# ATmega6490P device description
Architecture: AVR8; Family: megaAVR
Registers are 8-bit, access not given, no defined reset value unless marked. A register's access mark holds for its fields unless they carry their own. Offsets are from the block's base; [hi:lo] are bit positions; {n}, {i} and the like mark numbered series.

## TC0 (TC8 module) — Timer/Counter, 8-bit
Instances: TC0 0x00
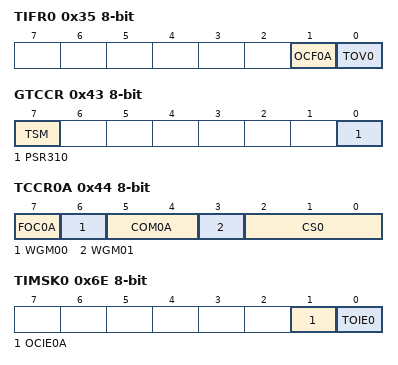
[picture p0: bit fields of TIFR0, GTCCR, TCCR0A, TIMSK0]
0x35 TIFR0 — Timer/Counter0 Interrupt Flag register
  [1] OCF0A — Timer/Counter0 Output Compare Flag 0
  [0] TOV0 — Timer/Counter0 Overflow Flag
0x43 GTCCR — General Timer/Control Register
  [7] TSM — Timer/Counter Synchronization Mode
  [0] PSR310 — Prescaler Reset Timer/Counter1 and Timer/Counter0
0x44 TCCR0A — Timer/Counter0 Control Register
  [7] FOC0A — Force Output Compare
  [6] WGM00 — Waveform Generation Mode 0
    0=Normal; 2=PWM, Phase Correct; 1=CTC; 3=Fast PWM
  [5:4] COM0A — Compare Match Output Modes
  [3] WGM01 — Waveform Generation Mode 1
  [2:0] CS0 — Clock Selects
    0=No Clock Source (Stopped); 1=Running, No Prescaling; 2=Running, CLK/8; 3=Running, CLK/64; 4=Running, CLK/256; 5=Running, CLK/1024; 6=Running, ExtClk Tx Falling Edge; 7=Running, ExtClk Tx Rising Edge
0x46 TCNT0 — Timer/Counter0
0x47 OCR0A — Timer/Counter0 Output Compare Register
0x6E TIMSK0 — Timer/Counter0 Interrupt Mask Register
  [1] OCIE0A — Timer/Counter0 Output Compare Match Interrupt Enable
  [0] TOIE0 — Timer/Counter0 Overflow Interrupt Enable

## TC1 (TC16 module) — Timer/Counter, 16-bit
Instances: TC1 0x00
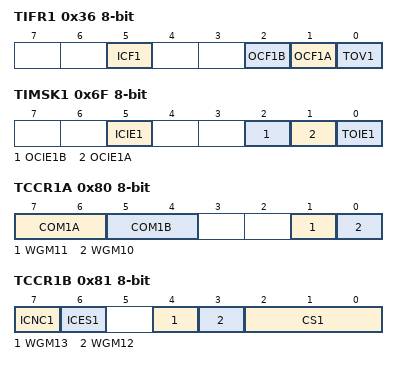
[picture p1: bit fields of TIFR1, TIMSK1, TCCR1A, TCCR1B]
0x36 TIFR1 — Timer/Counter1 Interrupt Flag register
  [5] ICF1 — Input Capture Flag 1
  [2] OCF1B — Output Compare Flag 1B
  [1] OCF1A — Output Compare Flag 1A
  [0] TOV1 — Timer/Counter1 Overflow Flag
0x6F TIMSK1 — Timer/Counter1 Interrupt Mask Register
  [5] ICIE1 — Timer/Counter1 Input Capture Interrupt Enable
  [2] OCIE1B — Timer/Counter1 Output Compare B Match Interrupt Enable
  [1] OCIE1A — Timer/Counter1 Output Compare A Match Interrupt Enable
  [0] TOIE1 — Timer/Counter1 Overflow Interrupt Enable
0x80 TCCR1A — Timer/Counter1 Control Register A
  [7:6] COM1A — Compare Output Mode 1A, bits
  [5:4] COM1B — Compare Output Mode 1B, bits
  [1] WGM11 — Waveform Generation Mode
  [0] WGM10 — Waveform Generation Mode
0x81 TCCR1B — Timer/Counter1 Control Register B
  [7] ICNC1 — Input Capture 1 Noise Canceler
  [6] ICES1 — Input Capture 1 Edge Select
  [4] WGM13 (bit 2 of the value upward) — Waveform Generation Mode
  [3] WGM12 (bit 2 of the value upward) — Waveform Generation Mode
  [2:0] CS1 — Prescaler source of Timer/Counter 1
    0=No Clock Source (Stopped); 1=Running, No Prescaling; 2=Running, CLK/8; 3=Running, CLK/64; 4=Running, CLK/256; 5=Running, CLK/1024; 6=Running, ExtClk Tx Falling Edge; 7=Running, ExtClk Tx Rising Edge
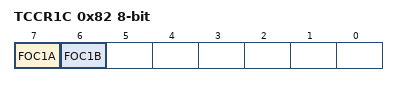
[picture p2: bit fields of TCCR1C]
0x82 TCCR1C — Timer/Counter 1 Control Register C
  [7] FOC1A — Force Output Compare 1A
  [6] FOC1B — Force Output Compare 1B
0x84 TCNT1 16-bit — Timer/Counter1 Bytes
0x86 ICR1 16-bit — Timer/Counter1 Input Capture Register Bytes
0x88 OCR1A 16-bit — Timer/Counter1 Output Compare Register A Bytes
0x8A OCR1B 16-bit — Timer/Counter1 Output Compare Register B Bytes

## TC2 (TC8_ASYNC module) — Timer/Counter, 8-bit Async
Instances: TC2 0x00
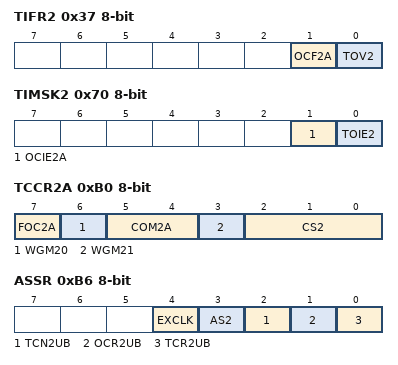
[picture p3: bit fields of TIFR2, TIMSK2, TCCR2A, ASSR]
0x37 TIFR2 — Timer/Counter2 Interrupt Flag Register
  [1] OCF2A — Timer/Counter2 Output Compare Flag 2
  [0] TOV2 — Timer/Counter2 Overflow Flag
0x43 GTCCR — General Timer/Counter Control Register
  [1] PSR2 — Prescaler Reset Timer/Counter2
0x70 TIMSK2 — Timer/Counter2 Interrupt Mask register
  [1] OCIE2A — Timer/Counter2 Output Compare Match Interrupt Enable
  [0] TOIE2 — Timer/Counter2 Overflow Interrupt Enable
0xB0 TCCR2A — Timer/Counter2 Control Register
  [7] FOC2A — Force Output Compare A
  [6] WGM20 — Waveform Generation Mode
    0=Normal; 2=PWM, Phase Correct; 1=CTC; 3=Fast PWM
  [5:4] COM2A — Compare Output Mode bits
  [3] WGM21 — Waveform Generation Mode
  [2:0] CS2 — Clock Select bits
    0=No Clock Source (Stopped); 1=Running, No Prescaling; 2=Running, CLK/8; 3=Running, CLK/32; 4=Running, CLK/64; 5=Running, CLK/128; 6=Running, CLK/256; 7=Running, CLK/1024
0xB2 TCNT2 — Timer/Counter2
0xB3 OCR2A — Timer/Counter2 Output Compare Register
0xB6 ASSR — Asynchronous Status Register
  [4] EXCLK — Enable External Clock Interrupt
  [3] AS2 — AS2: Asynchronous Timer/Counter2
  [2] TCN2UB — TCN2UB: Timer/Counter2 Update Busy
  [1] OCR2UB — Output Compare Register2 Update Busy
  [0] TCR2UB — TCR2UB: Timer/Counter Control Register2 Update Busy

## WDT — Watchdog Timer
Instances: WDT 0x00
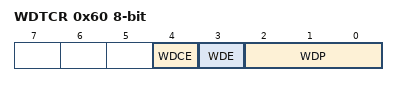
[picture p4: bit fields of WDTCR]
0x60 WDTCR — Watchdog Timer Control Register
  [4] WDCE — Watchdog Change Enable
  [3] WDE — Watch Dog Enable
  [2:0] WDP — Watch Dog Timer Prescaler bits
    0=Oscillator Cycles 16K; 1=Oscillator Cycles 32K; 2=Oscillator Cycles 64K; 3=Oscillator Cycles 128K; 4=Oscillator Cycles 256K; 5=Oscillator Cycles 512K; 6=Oscillator Cycles 1024K; 7=Oscillator Cycles 2048K

## BOOT_LOAD — Bootloader
Instances: BOOT_LOAD 0x00
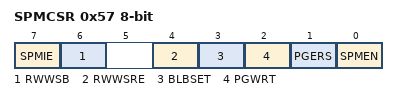
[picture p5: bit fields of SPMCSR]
0x57 SPMCSR — Store Program Memory Control Register
  [7] SPMIE — SPM Interrupt Enable
  [6] RWWSB — Read While Write Section Busy
  [4] RWWSRE — Read While Write section read enable
  [3] BLBSET — Boot Lock Bit Set
  [2] PGWRT — Page Write
  [1] PGERS — Page Erase
  [0] SPMEN — Store Program Memory Enable

## LCD — Liquid Crystal Display
Instances: LCD 0x00
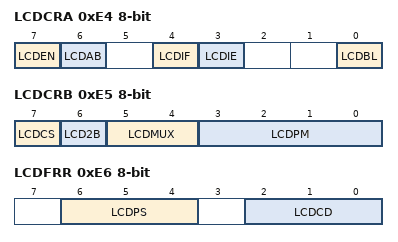
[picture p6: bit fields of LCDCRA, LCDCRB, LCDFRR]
0xE4 LCDCRA — LCD Control and Status Register A
  [7] LCDEN — LCD Enable
  [6] LCDAB — LCD A or B waveform
  [4] LCDIF — LCD Interrupt Flag
  [3] LCDIE — LCD Interrupt Enable
  [0] LCDBL — LCD Blanking
0xE5 LCDCRB — LCD Control and Status Register B
  [7] LCDCS — LCD CLock Select
  [6] LCD2B — LCD 1/2 Bias Select
  [5:4] LCDMUX — LCD Mux Selects
  [3:0] LCDPM — LCD Port Masks
    0=SEG0:12; 1=SEG0:14; 2=SEG0:15; 3=SEG0:18; 4=SEG0:20; 5=SEG0:22; 6=SEG0:23; 7=SEG0:24; 8=SEG0:26; 9=SEG0:28; 10=SEG0:30; 11=SEG0:32; 12=SEG0:34; 13=SEG0:36; 14=SEG0:38; 15=SEG0:39
0xE6 LCDFRR — LCD Frame Rate Register
  [6:4] LCDPS — LCD Prescaler Selects
    0=ClkLCD/16; 1=ClkLCD/64; 2=ClkLCD/128; 3=ClkLCD/256; 4=ClkLCD/512; 5=ClkLCD/1024; 6=ClkLCD/2048; 7=ClkLCD/4096
  [2:0] LCDCD — LCD Clock Dividers
    {v}={v+1} (v=0..7)
0xE7 LCDCCR bits used 7:5,3:0 — LCD Contrast Control Register
{0xEC+i} LCDDR{i} (i=0..19) — LCD Data Register {i}

## EXINT — External Interrupts
Instances: EXINT 0x00
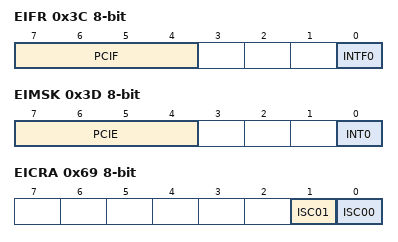
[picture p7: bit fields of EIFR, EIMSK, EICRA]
0x3C EIFR — External Interrupt Flag Register
  [7:4] PCIF — Pin Change Interrupt Flags
  [0] INTF0 — External Interrupt Flag 0
0x3D EIMSK — External Interrupt Mask Register
  [7:4] PCIE — Pin Change Interrupt Enables
  [0] INT0 — External Interrupt Request 0 Enable
0x69 EICRA — External Interrupt Control Register A
  [1] ISC01 — External Interrupt Sense Control 0 Bit 1
  [0] ISC00 — External Interrupt Sense Control 0 Bit 0
    0=Low Level of INTX; 1=Any Logical Change of INTX; 2=Falling Edge of INTX; 3=Rising Edge of INTX
{0x6B+i} PCMSK{i} (i=0..2) — Pin Change Mask Register {i}
0x73 PCMSK3 bits used 6:0 — Pin Change Mask Register 3
